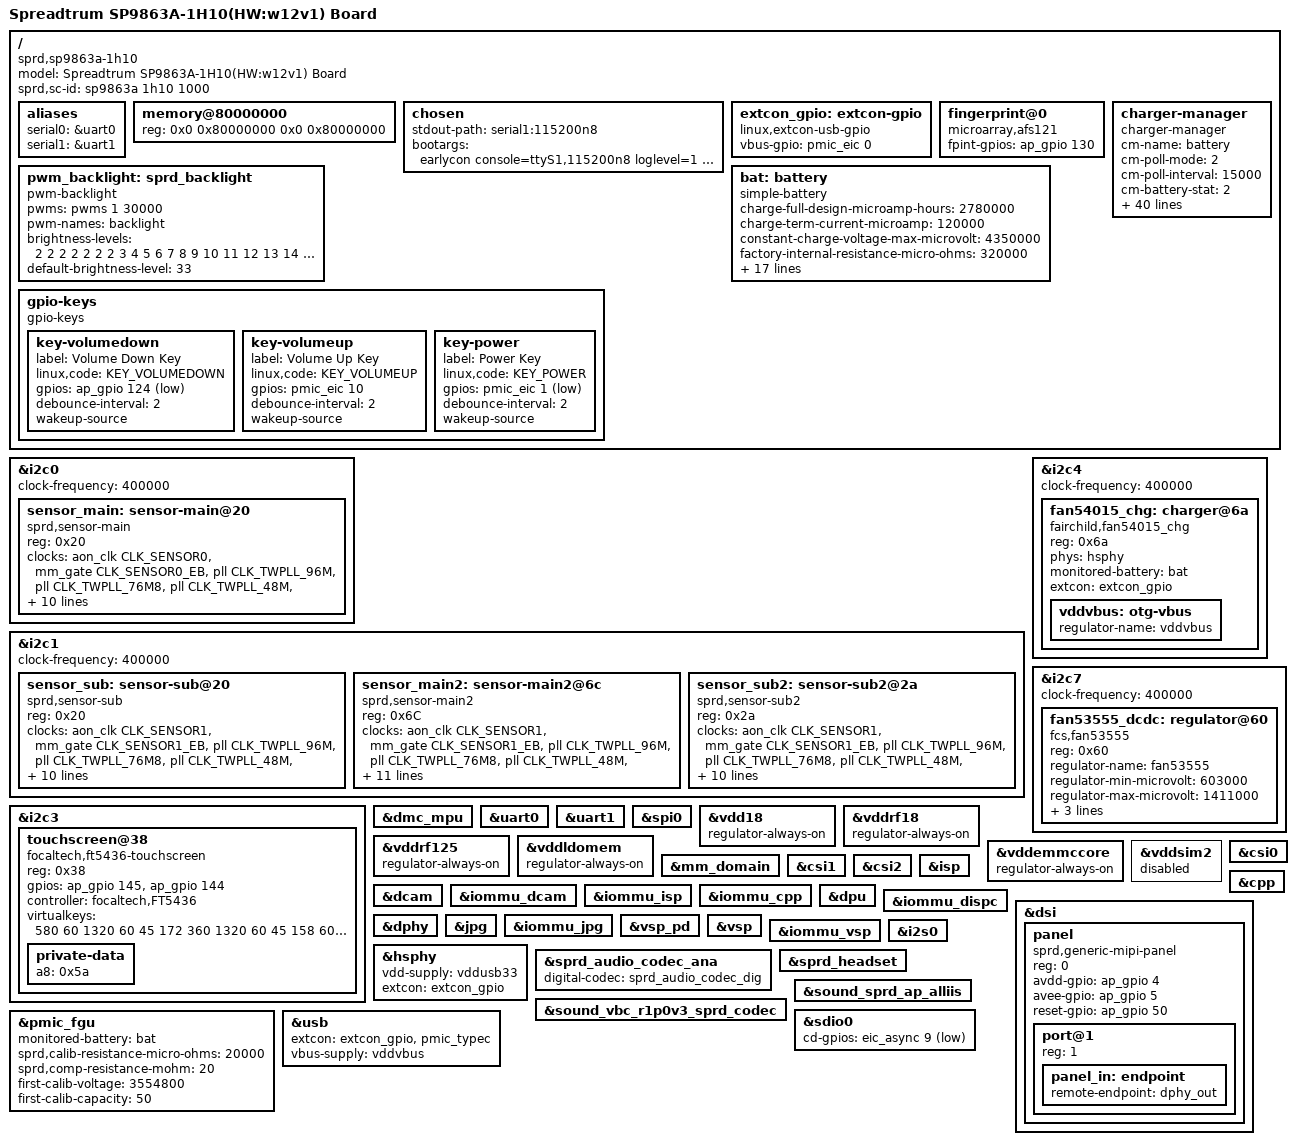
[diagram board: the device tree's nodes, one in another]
// SPDX-License-Identifier: GPL-2.0-only
/*
 * Unisoc SP9863A-1h10 boards DTS file
 *
 * Copyright (C) 2019, Unisoc Inc.
 */

/dts-v1/;
#include <dt-bindings/input/input.h>
#include <dt-bindings/gpio/gpio.h>
#include "sc9863a.dtsi"
#include "sc2721.dtsi"
#include "sprd-sound-sharkl.dtsi"
#include "sp9863a-mach.dtsi"
#include "sc9863a-wcn.dtsi"

#include "lcd/lcd_dummy_mipi.dtsi"
#include "lcd/lcd_nt35695_truly_mipi_fhd.dtsi"
#include "lcd/lcd_nt35532_truly_mipi_fhd.dtsi"
#include "lcd/lcd_nt35596_boe_mipi_fhd.dtsi"

/ {
	model = "Spreadtrum SP9863A-1H10(HW:w12v1) Board";

	compatible = "sprd,sp9863a-1h10", "sprd,sc9863a";

	sprd,sc-id = "sp9863a 1h10 1000";

	aliases {
		serial0 = &uart0;
		serial1 = &uart1;
	};

	memory@80000000 {
		device_type = "memory";
		reg = <0x0 0x80000000 0x0 0x80000000>;
	};

	chosen: chosen {
		stdout-path = "serial1:115200n8";
		bootargs = "earlycon console=ttyS1,115200n8 loglevel=1 init=/init root=/dev/ram0 rw printk.devkmsg=on androidboot.boot_devices=soc/soc:ap-ahb/20600000.sdio dummy_hcd.num=0 androidboot.hardware=s9863a1h10";
	};

	extcon_gpio: extcon-gpio {
		compatible = "linux,extcon-usb-gpio";
		vbus-gpio = <&pmic_eic 0 0>;
	};

	fingerprint@0 {
		compatible = "microarray,afs121";
		fpint-gpios = <&ap_gpio 130 0>;
	};

	pwm_backlight: sprd_backlight {
		compatible = "pwm-backlight";
		pwms = <&pwms 1 30000>;
		pwm-names = "backlight";
		brightness-levels = <
						  2   2   2   2
			  2   2   2   3   4   5   6   7   8   9
			 10  11  12  13  14  15  16  17  18  19
			 20  21  22  23  24  25  26  27  28  29
			 30  31  32  33  34  35  36  37  38  39
			 40  41  42  43  44  45  46  47  48  49
			 50  51  52  53  54  55  56  57  58  59
			 60  61  62  63  64  65  66  67  68  69
			 70  71  72  73  74  75  76  77  78  79
			 80  81  82  83  84  85  86  87  88  89
			 90  91  92  93  94  95  96  97  98  99
			100 101 102 103 104 105 106 107 108 109
			110 111 112 113 114 115 116 117 118 119
			120 121 122 123 124 125 126 127 128 129
			130 131 132 133 134 135 136 137 138 139
			140 141 142 143 144 145 146 147 148 149
			150 151 152 153 154 155 156 157 158 159
			160 161 162 163 164 165 166 167 168 169
			170 171 172 173 174 175 176 177 178 179
			180 181 182 183 184 185 186 187 188 189
			190 191 192 193 194 195 196 197 198 199
			200 201 202 203 204 205 206 207 208 209
			210 211 212 213 214 215 216 217 218 219
			220 221 222 223 224 225 226 227 228 229
			230 231 232 233 234 235 236 237 238 239
			240 241 242 243 244 245 246 247 248 249
			250 251
		>;
		default-brightness-level = <33>;
	};

	bat: battery {
		compatible = "simple-battery";
		charge-full-design-microamp-hours = <2780000>;
		charge-term-current-microamp = <120000>;
		constant-charge-voltage-max-microvolt = <4350000>;
		factory-internal-resistance-micro-ohms = <320000>;
		voltage-min-design-microvolt = <3450000>;
		ocv-capacity-celsius = <20>;
		ocv-capacity-table-0 = <4330000 100>, <4249000 95>, <4189000 90>,
					<4133000 85>, <4081000 80>, <4034000 75>,
					<3991000 70>, <3953000 65>, <3910000 60>,
					<3866000 55>, <3836000 50>, <3813000 45>,
					<3795000 40>, <3782000 35>, <3774000 30>,
					<3765000 25>, <3750000 20>, <3726000 15>,
					<3687000 10>, <3658000 5>, <3400000 0>;
		capacity-temp-table = <25 100>, <10 97>, <(-10) 60>;
		resistance-temp-table = <20 100>, <10 243>, <(-10) 468>;
		charge-sdp-current-microamp = <500000 500000>;
		charge-dcp-current-microamp = <1150000 3000000>;
		charge-cdp-current-microamp = <1150000 1150000>;
		charge-unknown-current-microamp = <1050000 1050000>;
	};

	charger-manager {
		status = "okay";
		compatible = "charger-manager";
		cm-name = "battery";
		cm-poll-mode = <2>;
		cm-poll-interval = <15000>;
		cm-battery-stat = <2>;

		cm-fullbatt-vchkdrop-ms = <30000>;
		cm-fullbatt-vchkdrop-volt = <60000>;
		cm-fullbatt-voltage = <4300000>;
		cm-fullbatt-current = <120000>;
		cm-fullbatt-capacity = <100>;

		cm-num-chargers = <1>;
		cm-chargers = "fan54015_charger";
		cm-fuel-gauge = "sc27xx-fgu";

		/* in deci centigrade */
		cm-battery-cold = <200>;
		cm-battery-cold-in-minus;
		cm-battery-hot = <800>;
		cm-battery-temp-diff = <100>;

		/* Allow charging for 6hr */
		cm-charging-max = <21600000>;
		/* recovery charging after stop charging 45min */
		cm-discharging-max = <2700000>;

		/* the interval to feed charger watchdog */
		cm-wdt-interval = <60>;

		/* drop voltage in microVolts to allow shutdown */
		cm-shutdown-voltage = <3100000>;

		/* when 99% of the time is exceeded, it will be forced to 100% */
		cm-tickle-time-out = <1500>;

		/* how much time to allow capacity change */
		cm-one-cap-time = <30>;

		/* when the safe charging voltage is exceeded, stop charging */
		cm-charge-voltage-max = <6500000>;
		/* drop voltage in microVolts to restart charging */
		cm-charge-voltage-drop = <700000>;
		cm-dcp-jeita-temp-table = <1000 1030 0 4350000>,
			<1150 1180 700000 4350000>,
			<1450 1420 1150000 4350000>,
			<1600 1570 700000 4100000>;
		cm-sdp-jeita-temp-table = <1000 1030 0 4350000>,
			<1150 1180 500000 4350000>,
			<1450 1420 500000 4350000>,
			<1600 1570 500000 4100000>;
		cm-cdp-jeita-temp-table = <1000 1030 0 4350000>,
			<1150 1180 700000 4350000>,
			<1450 1420 1150000 4350000>,
			<1600 1570 700000 4100000>;
		cm-unknown-jeita-temp-table = <1000 1030 0 4350000>,
			<1150 1180 700000 4350000>,
			<1450 1420 1050000 4350000>,
			<1600 1570 700000 4100000>;

		monitored-battery = <&bat>;

		cm-cap-remap-table = <1 2 3>, <2 3 2>, <98 99 2>, <99 100 3>;

	};
	gpio-keys {
		compatible = "gpio-keys";
		key-volumedown {
			label = "Volume Down Key";
			linux,code = <KEY_VOLUMEDOWN>;
			gpios = <&ap_gpio 124 GPIO_ACTIVE_LOW>;
			debounce-interval = <2>;
			wakeup-source;
		};
		key-volumeup {
			label = "Volume Up Key";
			linux,code = <KEY_VOLUMEUP>;
			gpios = <&pmic_eic 10 GPIO_ACTIVE_HIGH>;
			debounce-interval = <2>;
			wakeup-source;
		};
		key-power {
			label = "Power Key";
			linux,code =<KEY_POWER>;
			gpios = <&pmic_eic 1 GPIO_ACTIVE_LOW>;
			debounce-interval = <2>;
			wakeup-source;
		};
	};

};

&i2c0 {
	status = "okay";
	clock-frequency = <400000>;

	sensor_main: sensor-main@20 {
		compatible = "sprd,sensor-main";
		reg = <0x20>;
		clock-names = "clk_src","sensor_eb",
			"clk_96m","clk_76m8",
			"clk_48m","clk_26m";
		clocks = <&aon_clk CLK_SENSOR0>, <&mm_gate CLK_SENSOR0_EB>,
			<&pll CLK_TWPLL_96M>,<&pll CLK_TWPLL_76M8>,
			<&pll CLK_TWPLL_48M>,<&ext_26m>;
		vddio-supply = <&vddcamio>;
		vddcama-supply = <&vddcama>;
		vddcamd-supply = <&vddcamd>;
		vddcammot-supply = <&vddcammot>;
		sprd,phyid = <1>;
		csi = <&csi0>;
		reset-gpios = <&ap_gpio 44 0>;
		power-down-gpios = <&ap_gpio 46 0>;
		power-domains = <&mm_domain>;
	};
};

&i2c1 {
	status = "okay";
	clock-frequency = <400000>;

	sensor_sub: sensor-sub@20 {
		compatible = "sprd,sensor-sub";
		reg = <0x20>;
		clock-names = "clk_src","sensor_eb",
			"clk_96m","clk_76m8",
			"clk_48m","clk_26m";
		clocks = <&aon_clk CLK_SENSOR1>, <&mm_gate CLK_SENSOR1_EB>,
			<&pll CLK_TWPLL_96M>,<&pll CLK_TWPLL_76M8>,
			<&pll CLK_TWPLL_48M>,<&ext_26m>;
		vddio-supply = <&vddcamio>;
		vddcama-supply = <&vddcama>;
		vddcamd-supply = <&vddcamd>;
		vddcammot-supply = <&vddcammot>;
		sprd,phyid = <4>;
		csi = <&csi0>;
		reset-gpios = <&ap_gpio 41 0>;
		power-down-gpios = <&ap_gpio 40 0>;
		power-domains = <&mm_domain>;
	};

	sensor_main2: sensor-main2@6c {
		compatible = "sprd,sensor-main2";
		reg = <0x6C>;
		clock-names = "clk_src","sensor_eb",
			"clk_96m","clk_76m8",
			"clk_48m","clk_26m";
		clocks = <&aon_clk CLK_SENSOR1>, <&mm_gate CLK_SENSOR1_EB>,
			<&pll CLK_TWPLL_96M>,<&pll CLK_TWPLL_76M8>,
			<&pll CLK_TWPLL_48M>,<&ext_26m>;
		vddio-supply = <&vddcamio>;
		vddcama-supply = <&vddcama>;
		vddcamd-supply = <&vddcamd>;
		vddcammot-supply = <&vddcammot>;
		sprd,phyid = <3>;
		csi = <&csi1>;
		/*avdd-gpios=<&ap_gpio 140 0>;*/
		dvdd-gpios=<&ap_gpio 62 0>;
		reset-gpios = <&ap_gpio 45 0>;
		power-down-gpios = <&ap_gpio 47 0>;
		power-domains = <&mm_domain>;
	};

	sensor_sub2: sensor-sub2@2a {
		compatible = "sprd,sensor-sub2";
		reg = <0x2a>;
		clock-names = "clk_src","sensor_eb",
			"clk_96m","clk_76m8",
			"clk_48m","clk_26m";
		clocks = <&aon_clk CLK_SENSOR1>, <&mm_gate CLK_SENSOR1_EB>,
			<&pll CLK_TWPLL_96M>,<&pll CLK_TWPLL_76M8>,
			<&pll CLK_TWPLL_48M>,<&ext_26m>;
		vddio-supply = <&vddcamio>;
		vddcama-supply = <&vddcama>;
		vddcamd-supply = <&vddcamd>;
		vddcammot-supply = <&vddcammot>;
		sprd,phyid = <4>;
		csi = <&csi2>;
		/*avdd-gpios=<&ap_gpio 140 0>;*/
		reset-gpios = <&ap_gpio 45 0>;
		power-down-gpios = <&ap_gpio 40 0>;
		power-domains = <&mm_domain>;
	};
};

&i2c3 {
	status = "okay";

	touchscreen@38 {
		compatible = "focaltech,ft5436-touchscreen";
		reg = <0x38>;
		gpios = <&ap_gpio 145 GPIO_ACTIVE_HIGH
			&ap_gpio 144 GPIO_ACTIVE_HIGH>;
		controller = "focaltech,FT5436";
		virtualkeys = <580 60 1320 60 45
			172 360 1320 60 45
			158 600 1320 60 45>;
		private-data {
			a8 = /bits/ 8 <0x5a>;
		};
	};
};

&i2c4 {
	#address-cells = <1>;
	#size-cells = <0>;

	status = "okay";
	clock-frequency = <400000>;

	fan54015_chg: charger@6a {
		compatible = "fairchild,fan54015_chg";
		reg = <0x6a>;
		phys = <&hsphy>;
		monitored-battery = <&bat>;
		extcon = <&extcon_gpio>;
		vddvbus:otg-vbus {
			regulator-name = "vddvbus";
		};
	};
};

&i2c7 {
	status = "okay";
};

&dmc_mpu {
	status = "okay";
};

&uart0 {
	status = "okay";
};

&uart1 {
	status = "okay";
};

&spi0 {
	/*used for fingerprint sensor*/
	status = "okay";
};

&vdd18 {
	regulator-always-on;
};

&vddrf18 {
	regulator-always-on;
};

&vddrf125 {
	regulator-always-on;
};

&vddldomem {
	regulator-always-on;
};

&vddemmccore {
	regulator-always-on;
};

&vddsim2 {
	status = "disabled";
};

&i2c7 {
	status = "okay";
	clock-frequency = <400000>;

	fan53555_dcdc: regulator@60 {
		compatible = "fcs,fan53555";
		reg = <0x60>;
		regulator-name = "fan53555";
		regulator-min-microvolt = <603000>;
		regulator-max-microvolt = <1411000>;
		regulator-ramp-delay = <64000>;
		regulator-always-on;
		fcs,suspend-voltage-selector = <1>;
	};
};

&mm_domain {
	status = "okay";
};

&csi0 {
	status = "okay";
};

&csi1 {
	status = "okay";
};

&csi2 {
	status = "okay";
};

&dcam {
	status = "okay";
};

&iommu_dcam {
	status = "okay";
};

&isp {
	status = "okay";
};

&iommu_isp {
	status = "okay";
};

&cpp {
	status = "okay";
};

&iommu_cpp {
	status = "okay";
};

&dpu {
	status = "okay";
};

&iommu_dispc {
	status = "okay";
};

&dsi {
	status = "okay";
	#address-cells = <1>;
	#size-cells = <0>;

	panel: panel {
		compatible = "sprd,generic-mipi-panel";
		#address-cells = <1>;
		#size-cells = <0>;
		reg = <0>;

		avdd-gpio = <&ap_gpio 4 GPIO_ACTIVE_HIGH>;
		avee-gpio = <&ap_gpio 5 GPIO_ACTIVE_HIGH>;
		reset-gpio = <&ap_gpio 50 GPIO_ACTIVE_HIGH>;
		port@1 {
			reg = <1>;
			panel_in: endpoint {
				remote-endpoint = <&dphy_out>;
			};
		};
	};
};

&dphy {
	status = "okay";
};

&jpg {
	status = "okay";
};

&iommu_jpg {
	status = "okay";
};

&vsp_pd {
	status = "okay";
};

&vsp {
	status = "okay";
};

&iommu_vsp {
	status = "okay";
};

&hsphy {
	vdd-supply = <&vddusb33>;
	extcon = <&extcon_gpio>;
	status = "okay";
};

&i2s0 {
	status = "okay";
};

&sprd_audio_codec_ana {
	status = "okay";
	digital-codec = <&sprd_audio_codec_dig>;
};

&sprd_headset {
	status = "okay";
};

&sound_vbc_r1p0v3_sprd_codec {
	status = "okay";
};

&sound_sprd_ap_alliis {
	status = "okay";
};

&pmic_fgu {
	monitored-battery = <&bat>;
	sprd,calib-resistance-micro-ohms = <20000>;
	sprd,comp-resistance-mohm = <20>;
	first-calib-voltage = <3554800>;
	first-calib-capacity = <50>;
};

&usb{
	extcon = <&extcon_gpio>, <&pmic_typec>;
	status = "okay";
	vbus-supply = <&vddvbus>;
};

&sdio0 {
	cd-gpios = <&eic_async 9 1>;
};
